# R7KA8T2AD register map
Vendor: Renesas Electronics Corporation; Series: RA8; File version: 1.10.02
CPU: CM85 r0p2, little endian, MPU, FPU, VTOR, 4 interrupt priority bits, 96 interrupts
Registers are 32-bit, read-write, reset 0x0 unless marked. A register's access mark holds for its fields unless they carry their own. Offsets are from the block's base; [hi:lo] are bit positions; {n}, {i} and the like mark numbered series; 'fields as' and 'values as' point back to an identical list.

## MFWD (part 1 of 2) — Forwarding engine
Base 0x403C0000
Same registers: MFWD_NS 0x503C0000
0x00 FWGC — General Configuration Register
  [1:0] SVM — Switch VLAN Mode
    0=No VLAN mode (VLAN not used for forwarding); 1=C-TAG mode (C-TAG used for forwarding); 2=SC-TAG mode (S-TAG used for forwarding)
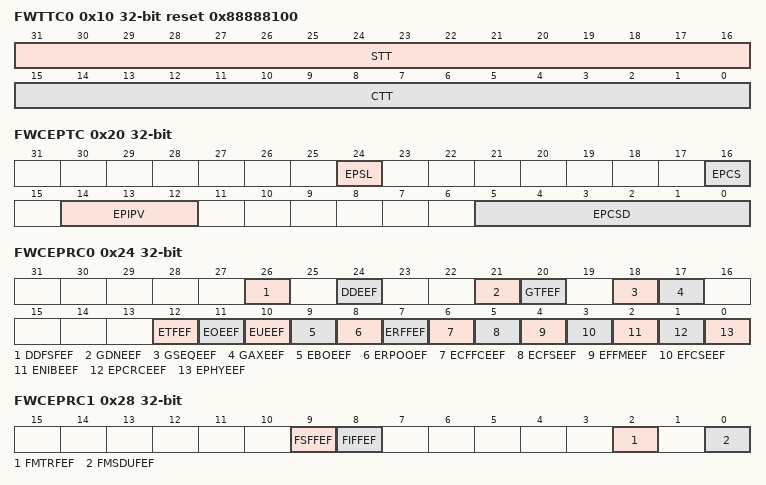
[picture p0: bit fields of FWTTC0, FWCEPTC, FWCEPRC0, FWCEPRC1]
0x10 FWTTC0 reset 0x88888100 — TAG TPID Configuration Register 0
  [31:16] STT — S-TAG TPID [801.2Q]
  [15:0] CTT — C-TAG TPID [801.2Q]
0x14 FWTTC1 reset 0xF1C1 — TAG TPID Configuration Register 1
  [15:0] RTT — R-TAG TPID [801.2CB]
0x20 FWCEPTC — CPU Exceptional Path Target Configuration Register
  [24] EPSL — Exceptional Path Security Level
  [16] EPCS — Exceptional Path CPU Select
  [14:12] EPIPV — Exceptional Path Internal Priority Value
  [5:0] EPCSD — Exceptional Path CPU Sub Destination
0x24 FWCEPRC0 — CPU Exceptional Path Reason Configuration Register 0
  [26] DDFSFEF — Direct Descriptor Format Security Filtering Exceptional Forwarding
    0=Frames with Direct Descriptor Format Security Error are discarded; 1=Frames with Direct Descriptor Format Security Error are forwarded to exceptional path
  [24] DDEEF — Direct Descriptor Error Exceptional Forwarding
    0=Frames with Direct Descriptor Error are discarded; 1=Frames with Direct Descriptor Error are forwarded to exceptional path
  [21] GDNEEF — GWCA Descriptor Number Error Exceptional Forwarding
    0=Frames received with Descriptor Number Error are discarded; 1=Frames received with Descriptor Number Error are forwarded to exceptional path
  [20] GTFEF — GWCA TAG Filtering Exceptional Forwarding
    0=Frames received with TAG Filtering flag are discarded; 1=Frames received with TAG Filtering flag are forwarded to exceptional path
  [18] GSEQEEF — GWCA Sequence Error Exceptional Forwarding
    0=Frames received with Sequence Error are discarded; 1=Frames received with Sequence Error are forwarded to exceptional path
  [17] GAXEEF — GWCA AXI Error Exceptional Forwarding
    0=Frames received with AXI Error are discarded; 1=Frames received with AXI Error are forwarded to exceptional path
  [12] ETFEF — Ethernet TAG Filtering Exceptional Forwarding
    values as GTFEF
  [11] EOEEF — Ethernet Oversize Error Exceptional Forwarding
    0=Frames received with Oversize Error are discarded; 1=Frames received with Oversize Error are forwarded to exceptional path
  [10] EUEEF — Ethernet Undersize Error Exceptional Forwarding
    0=Frames received with Undersize Error are discarded; 1=Frames received with Undersize Error are forwarded to exceptional path
  [9] EBOEEF — Ethernet Buffer Overflow Error Exceptional Forwarding
    0=Frames received with Buffer Overflow Error are discarded; 1=Frames received with Buffer Overflow Error are forwarded to exceptional path
  [8] ERPOOEF — Ethernet Reception Partially Out of Operation Exceptional Forwarding
    0=Frames received with Reception Partially Out of Operation flag are discarded; 1=Frames received with Reception Partially Out of Operation flag are forwarded to exceptional path
  [7] ERFFEF — Ethernet RMAC Frame Filtered Exceptional Forwarding
    0=Frames received with RMAC Frame Filtered flag are discarded; 1=Frames received with RMAC Frame Filtered flag are forwarded to exceptional path
  [6] ECFFCEEF — Ethernet C-Fragment FRAG_COUNT Error Exceptional Forwarding
    0=Frames received with C-Fragment FRAG_COUNT Error are discarded; 1=Frames received with C-Fragment FRAG_COUNT Error are forwarded to exceptional path
  [5] ECFSEEF — Ethernet C-Fragment SMD Error Exceptional Forwarding
    0=Frames received with C-Fragment SMD Error are discarded; 1=Frames received with C-Fragment SMD Error are forwarded to exceptional path
  [4] EFFMEEF — Ethernet Final Fragment Missing Error Exceptional Forwarding
    0=Frames received with Final Fragment Missing Error are discarded; 1=Frames received with Final Fragment Missing Error are forwarded to exceptional path
  [3] EFCSEEF — Ethernet FCS Error Exceptional Forwarding
    0=Frames received with FCS Error are discarded; 1=Frames received with FCS Error are forwarded to exceptional path
  [2] ENIBEEF — Ethernet Nibble Error Exceptional Forwarding
    0=Frames received with Nibble Error are discarded; 1=Frames received with Nibble Error are forwarded to exceptional path
  [1] EPCRCEEF — Ethernet PCH CRC Error Exceptional Forwarding
    0=Frames received with PCH CRC Error are discarded; 1=Frames received with PCH CRC Error are forwarded to exceptional path
  [0] EPHYEEF — Ethernet PHY Error Exceptional Forwarding
    0=Frames received with PHY Error are discarded; 1=Frames received with PHY Error are forwarded to exceptional path
0x28 FWCEPRC1 — CPU Exceptional Path Reason Configuration Register 1
  [9] FSFFEF — Sequence FRER Filtering Exceptional Forwarding
    0=Frames filtered by FRER Sequence recovery are discarded; 1=Frames filtered by FRER Sequence recovery are forwarded to exceptional path
  [8] FIFFEF — Individual FRER Filtering Exceptional Forwarding
    0=Frames filtered by FRER individual recovery are discarded; 1=Frames filtered by FRER individual recovery are forwarded to exceptional path
  [2] FMTRFEF — Meter Filtering Exceptional Forwarding
    0=Frames filtered by PSFP Meter filter are discarded; 1=Frames filtered by PSFP Meter filter are forwarded to exceptional path
  [0] FMSDUFEF — MSDU Filtering Exceptional Forwarding
    0=Frames filtered by PSFP MSDU filter are discarded; 1=Frames filtered by PSFP MSDU filter are forwarded to exceptional path
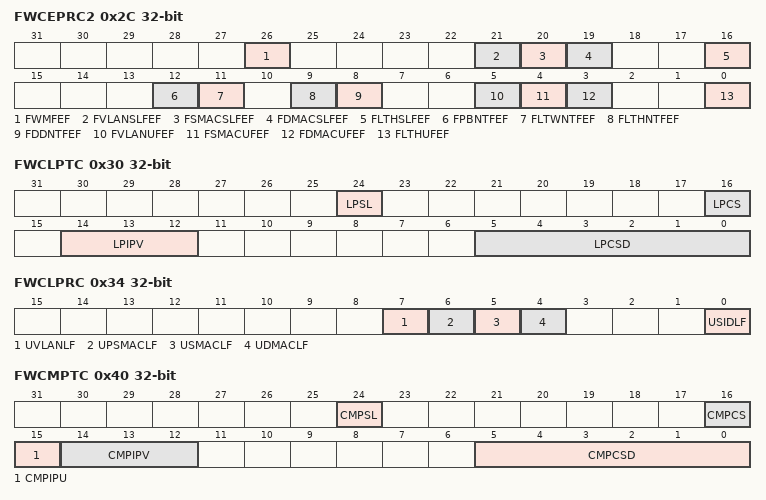
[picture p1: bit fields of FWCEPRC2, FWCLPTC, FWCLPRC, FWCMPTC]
0x2C FWCEPRC2 — CPU Exceptional Path Reason Configuration Register 2
  [26] FWMFEF — Watermark Filtering Exceptional Forwarding
    0=Frames filtered because of watermark are discarded; 1=Frames filtered because of watermark are forwarded to exceptional path
  [21] FVLANSLFEF — VLAN Source Lock Filtering Exceptional Forwarding
    0=Frames filtered because of VLAN source lock are discarded; 1=Frames filtered because of VLAN source lock are forwarded to exceptional path
  [20] FSMACSLFEF — Source MAC Source Lock Filtering Exceptional Forwarding
    0=Frames filtered because of Source MAC source lock are discarded; 1=Frames filtered because of Source MAC source lock are forwarded to exceptional path
  [19] FDMACSLFEF — Destination MAC Source Lock Filtering Exceptional Forwarding
    0=Frames filtered because of Destination MAC source lock are discarded; 1=Frames filtered because of Destination MAC source lock are forwarded to exceptional path
  [16] FLTHSLFEF — Layer 3 Source Lock Filtering Exceptional Forwarding
    0=Frames filtered because of Layer 3 source lock are discarded; 1=Frames filtered because of Layer 3 source lock are forwarded to exceptional path
  [12] FPBNTFEF — Port Based No Target Filtering Exceptional Forwarding
    0=Frames filtered because no target during Port Based forwarding is detected are discarded; 1=Frames filtered because no target during Port Based forwarding is detected are forwarded to exceptional path
  [11] FLTWNTFEF — Layer 2 No Target Filtering Exceptional Forwarding
    0=Frames filtered because the combination on VLAN destination vector and destination MAC destination vector is null are discarded; 1=Frames filtered because the combination on VLAN destination vector and destination MAC destination vector is null are forwarded to exceptional path
  [9] FLTHNTFEF — Layer 3 No Target Filtering Exceptional Forwarding
    0=Frames filtered because no target during Layer 3 forwarding is detected are discarded; 1=Frames filtered because no target during Layer 3 forwarding is detected are forwarded to exceptional path
  [8] FDDNTFEF — Direct Descriptor No Target Filtering Exceptional Forwarding
    0=Frames filtered because no target during direct forwarding is detected are discarded; 1=Frames filtered because no target during direct forwarding is detected are forwarded to exceptional path
  [5] FVLANUFEF — VLAN Unknown Filtering Exceptional Forwarding
    0=Frames filtered because their VLAN is unknown are discarded; 1=Frames filtered because their VLAN is unknown are forwarded to exceptional path
  [4] FSMACUFEF — Source MAC Unknown Filtering Exceptional Forwarding
    0=Frames filtered because their Source MAC is unknown are discarded; 1=Frames filtered because their Source MAC is unknown are forwarded to exceptional path
  [3] FDMACUFEF — Destination MAC Unknown Filtering Exceptional Forwarding
    0=Frames filtered because their Destination MAC is unknown are discarded; 1=Frames filtered because their Destination MAC is unknown are forwarded to exceptional path
  [0] FLTHUFEF — Layer 3 Unknown Filtering Exceptional Forwarding
    0=Frames filtered because their stream ID is unknown are discarded; 1=Frames filtered because their stream ID is unknown are forwarded to exceptional path
0x30 FWCLPTC — CPU Learning Path Target Configuration Register
  [24] LPSL — Learning Path Security Level
  [16] LPCS — Learning Path CPU Select
  [14:12] LPIPV — Learning Path Internal Priority Value
  [5:0] LPCSD — Learning Path CPU Sub Destination
0x34 FWCLPRC — CPU Learning Path Reason Configuration Register
  [7] UVLANLF — Unknown VLAN Learning Forwarding
    0=Frames received with an unknown VLAN are not forwarded to Learning path; 1=Frames received with an unknown VLAN are forwarded to Learning path
  [6] UPSMACLF — Unknown Port for Source MAC Learning Forwarding
    0=Frames received with an unknown port for Source MAC are not forwarded to Learning path; 1=Frames received with an unknown port for Source MAC are forwarded to Learning path
  [5] USMACLF — Unknown Source MAC Learning Forwarding
    0=Frames received with an unknown Source MAC are not forwarded to Learning path; 1=Frames received with an unknown Source MAC are forwarded to Learning path
  [4] UDMACLF — Unknown Destination MAC Learning Forwarding
    0=Frames received with an unknown destination MAC address are not forwarded to Learning path; 1=Frames received with an unknown destination MAC address are forwarded to Learning path
  [0] USIDLF — Unknown Stream ID Learning Forwarding
    0=Frames received with an unknown stream ID are not forwarded to Learning path; 1=Frames received with an unknown stream ID are forwarded to Learning path
0x40 FWCMPTC — CPU Mirroring Path Target Configuration Register
  [24] CMPSL — CPU Mirroring Path Security Level
  [16] CMPCS — CPU Mirroring Path CPU Select
  [15] CMPIPU — CPU Mirroring Path Internal Priority Update
    0=Frames mirrored to CPU path are sent with the same priority as for forwarding; 1=Frames mirrored to CPU path are sent with FWCMPTC.CMPIPV priority
  [14:12] CMPIPV — CPU Mirroring Path Internal Priority Value
  [5:0] CMPCSD — CPU Mirroring Path CPU Sub Destination
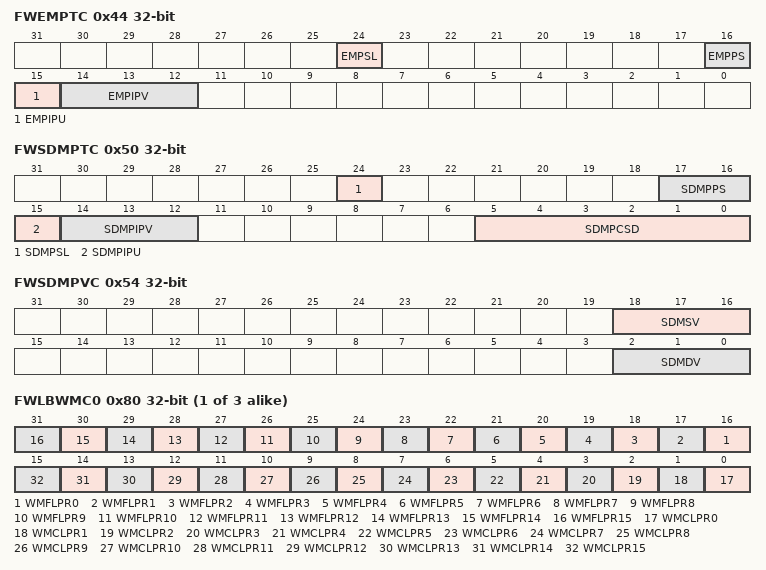
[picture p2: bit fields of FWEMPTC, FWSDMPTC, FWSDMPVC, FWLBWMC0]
0x44 FWEMPTC — Ethernet Mirroring Path Target Configuration Register
  [24] EMPSL — Ethernet Mirroring Path Security Level
  [16] EMPPS — Ethernet Mirroring Path Port Select
  [15] EMPIPU — Ethernet Mirroring Path Internal Priority Update
    0=Frames mirrored to Ethernet path are sent with the same priority as for forwarding; 1=Frames mirrored to Ethernet path are sent with FWEMPTC.EMPIPV priority
  [14:12] EMPIPV — Ethernet Mirroring Path Internal Priority Value
0x50 FWSDMPTC — Source-Destination Mirroring Path Target Configuration Register
  [24] SDMPSL — Source-Destination Mirroring Path Security Level
  [17:16] SDMPPS — Source-Destination Mirroring Path Port Select
  [15] SDMPIPU — Source-Destination Mirroring Path Internal Priority Update
    0=Frames mirrored to Source-Destination path are sent with the same priority as for forwarding; 1=Frames mirrored to Source-Destination path are sent with FWSDMPTC.SDMPIPV priority
  [14:12] SDMPIPV — Source-Destination Mirroring Path Internal Priority Value
  [5:0] SDMPCSD — Source-Destination Mirroring Path CPU Sub Destination
0x54 FWSDMPVC — Source-Destination Mirroring Path Vector Configuration Register
  [18:16] SDMSV — Source-Destination Mirroring Source Vector
  [2:0] SDMDV — Source-Destination Mirroring Destination Vector
{0x80+4i} FWLBWMC{i} (i=0..2) — Port {i} Level Based Watermark Configuration Register
  [n+16] WMFLPR{n} (n=0..15) — Watermark Flush Level Priority n Reject (n = 0 to 15)
    0=Frames coming for port i and that should be forwarded with {DEI,IPV} equal to j are forwarded; 1=Frames coming for port i and that should be forwarded with {DEI,IPV} equal to j are discarded when watermark flush level is set for port i (WM.FLUSH[i] is set [COMA])
  [n] WMCLPR{n} (n=0..15) — Watermark Critical Level Priority n Reject (n = 0 to 15)
    0=Frames coming for port i and that should be forwarded with {DEI,IPV} equal to j are forwarded; 1=Frames coming for port i and that should be forwarded with {DEI,IPV} equal to j are discarded when watermark critical level is set for port i (WM.CRITICAL[i] is set [COMA])
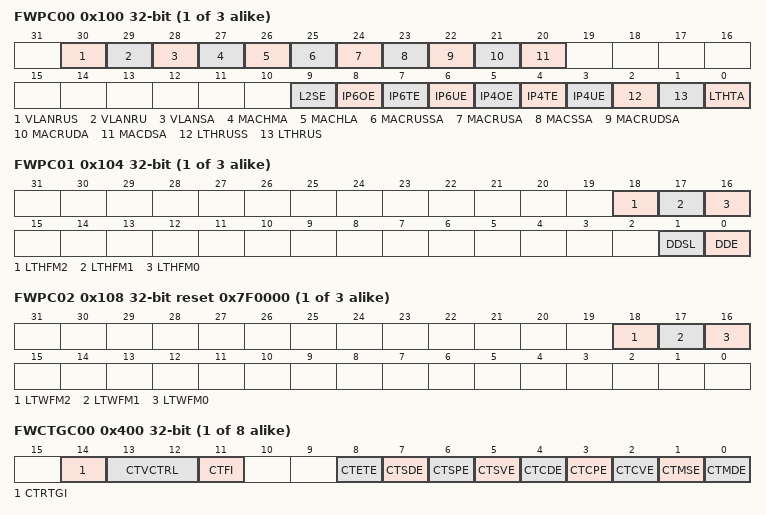
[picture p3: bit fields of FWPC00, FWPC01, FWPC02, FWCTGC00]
{0x100+0x10*i} FWPC{i}0 (i=0..2) — Port {i} Configuration Register 0
  [30] VLANRUS — VLAN Reject Unknown Secure
    0=Unknown secure VLAN coming from source port i are not rejected; 1=Unknown secure VLAN coming from source port i are rejected
  [29] VLANRU — VLAN Reject Unknown
    0=Unknown VLAN coming from source port i are not rejected; 1=Unknown VLAN coming from source port i are rejected
  [28] VLANSA — VLAN Search Active
    0=VLAN search is disabled for source port i; 1=VLAN search is enabled for source port i
  [27] MACHMA — MAC Hardware Migration Active
    0=Known unicast MAC Source addresses coming from source port i with a wrong source port in MAC.DV are not overwritten; 1=Known unicast MAC Source addresses coming from source port i with a wrong source port in MAC.DV are overwritten
  [26] MACHLA — MAC Hardware Learning Active
    0=Unknown unicast MAC Source addresses coming from source port i are not added to the MAC table; 1=Unknown unicast MAC Source addresses coming from source port i are added to the MAC table
  [25] MACRUSSA — MAC Reject Unknown Source Secure Addresses
    0=Unknown secure MAC Source addresses coming from source port i are not rejected; 1=Unknown secure MAC Source addresses coming from source port i are rejected
  [24] MACRUSA — MAC Reject Unknown Source Addresses
    0=Unknown MAC Source addresses coming from source port i are not rejected; 1=Unknown MAC Source addresses coming from source port i are rejected
  [23] MACSSA — MAC Source Search Active
    0=MAC Source search is disabled for source port i; 1=MAC Source search is enabled for source port i
  [22] MACRUDSA — MAC Reject Unknown Destination Secure Addresses
    0=Unknown secure MAC Destination addresses coming from source port i are not rejected; 1=Unknown secure MAC Destination addresses coming from source port i are rejected
  [21] MACRUDA — MAC Reject Unknown Destination Addresses
    0=Unknown MAC Destination addresses coming from source port i are not rejected; 1=Unknown MAC Destination addresses coming from source port i are rejected
  [20] MACDSA — MAC Destination Search Active
    0=MAC Destination search is disabled for source port i; 1=MAC Destination search is enabled for source port i
  [9] L2SE — L2 Stream Enable
    0=L2 stream disabled for source port i; 1=L2 stream enabled for source port i
  [8] IP6OE — IPv6 Other Enable
    0=Non-TCP non-UDP IPv6 detection disabled for source port i; 1=Non-TCP non-UDP IPv6 detection enabled for source port i
  [7] IP6TE — IPv6 TCP Enable
    0=IPv6/TCP detection disabled for source port i; 1=IPv6/TCP detection enabled for source port i
  [6] IP6UE — IPv6 UDP Enable
    0=IPv6/UDP detection disabled for source port i; 1=IPv6/UDP detection enabled for source port i
  [5] IP4OE — IPv4 Other Enable
    0=Non-TCP non-UDP IPv4 detection disabled for source port i; 1=Non-TCP non-UDP IPv4 detection enabled for source port i
  [4] IP4TE — IPv4 TCP Enable
    0=IPv4/TCP detection disabled for source port i; 1=IPv4/TCP detection enabled for source port i
  [3] IP4UE — IPv4 UDP Enable
    0=IPv4/UDP detection disabled for source port i; 1=IPv4/UDP detection enabled for source port i
  [2] LTHRUSS — L3 Reject Unknown Secure Streams
    0=Unknown secure streams coming from source port i are not rejected; 1=Unknown secure streams coming from source port i are rejected
  [1] LTHRUS — L3 Reject Unknown Streams
    0=Unknown streams coming from source port i are not rejected; 1=Unknown streams coming from source port i are rejected
  [0] LTHTA — L3 Table Active
    0=L3 table is disabled for source port i; 1=L3 table is enabled for source port i
{0x104+0x10*i} FWPC{i}1 (i=0..2) — Port {i} Configuration Register 1
  [18] LTHFM2 — Layer 3 Forwarding Mask n (n = 0 to 2)
    0=Frames forwarded by Layer 3 forwarding can be forwarded to port j; 1=Frames forwarded by Layer 3 forwarding cannot be forwarded to port j
  [17] LTHFM1 — Layer 3 Forwarding Mask n (n = 0 to 2)
    values as LTHFM2
  [16] LTHFM0 — Layer 3 Forwarding Mask n (n = 0 to 2)
    values as LTHFM2
  [1] DDSL — Direct Descriptor Security Level
    0=Secured Direct Descriptor discarded for port i; 1=Secured Direct Descriptor forwarded for port i
  [0] DDE — Direct Descriptor Enable
    0=Direct Descriptor disabled for port i; 1=Direct Descriptor enabled for port i
{0x108+0x10*i} FWPC{i}2 (i=0..2) reset 0x7F0000 — Port {i} Configuration Register 2
  [all] fields
    0=Frames forwarded by Layer 2 forwarding can be forwarded to port j; 1=Frames forwarded by Layer 2 forwarding cannot be forwarded to port j
  [18] LTWFM2 — Layer 2 Forwarding Mask n (n = 0 to 2)
  [17] LTWFM1 — Layer 2 Forwarding Mask n (n = 0 to 2)
  [16] LTWFM0 — Layer 2 Forwarding Mask n (n = 0 to 2)
{0x400+0x40*i} FWCTGC{i}0 (i=0..7) — Cut-Through General Configuration Register i0
  [14] CTRTGI — Cut-Through R-TAG In [GWCA] [ETHA]
    0=R-TAG is not included in cut-through frame; 1=R-TAG is included in cut-through frame
  [13:12] CTVCTRL — Cut-Through VLAN Control [GWCA] [ETHA]
    0=The ingress matching separation rule i frame is a No TAG frame; 1=The ingress matching separation rule i frame is a C-TAG frame; 2=The ingress matching separation rule i frame is an SC-TAG frame; 3=The ingress matching separation rule i frame is a CoS TAG frame
  [11] CTFI — Cut-Through FCS In
    0=The frame matching separation rule i as no FCS included; 1=The frame matching separation rule i as an FCS included
  [8] CTETE — Cut-Through Ethernet Type Enable
    0=Ethernet Type not included in Cut-Through separation for separation rule i; 1=Ethernet Type included in Cut-Through separation for separation rule i
  [7] CTSDE — Cut-Through S-TAG DEI Enable
    0=S-TAG DEI not included in Cut-Through separation for separation rule i; 1=S-TAG DEI included in Cut-Through separation for separation rule i
  [6] CTSPE — Cut-Through S-TAG PCP Enable
    0=S-TAG PCP not included in Cut-Through separation for separation rule i; 1=S-TAG PCP included in Cut-Through separation for separation rule i
  [5] CTSVE — Cut-Through S-TAG VLAN Enable
    0=S-TAG VLAN not included in Cut-Through separation for separation rule i; 1=S-TAG VLAN included in Cut-Through separation for separation rule i
  [4] CTCDE — Cut-Through C-TAG DEI Enable
    0=C-TAG DEI not included in Cut-Through separation for separation rule i; 1=C-TAG DEI included in Cut-Through separation for separation rule i
  [3] CTCPE — Cut-Through C-TAG PCP Enable
    0=C-TAG PCP not included in Cut-Through separation for separation rule i; 1=C-TAG PCP included in Cut-Through separation for separation rule i
  [2] CTCVE — Cut-Through C-TAG VLAN Enable
    0=C-TAG VLAN not included in Cut-Through separation for separation rule i; 1=C-TAG VLAN included in Cut-Through separation for separation rule i
  [1] CTMSE — Cut-Through MAC Source Enable
    0=MAC Source not included in Cut-Through separation for separation rule i; 1=MAC Source included in Cut-Through separation for separation rule i
  [0] CTMDE — Cut-Through MAC Destination Enable
    0=MAC destination not included in Cut-Through separation for separation rule i; 1=MAC destination included in Cut-Through separation for separation rule i
{0x404+0x40*i} FWCTGC{i}1 (i=0..7) — Cut-Through General Configuration Register i1
  [25:0] CTMT — Cut-Through Maximum time
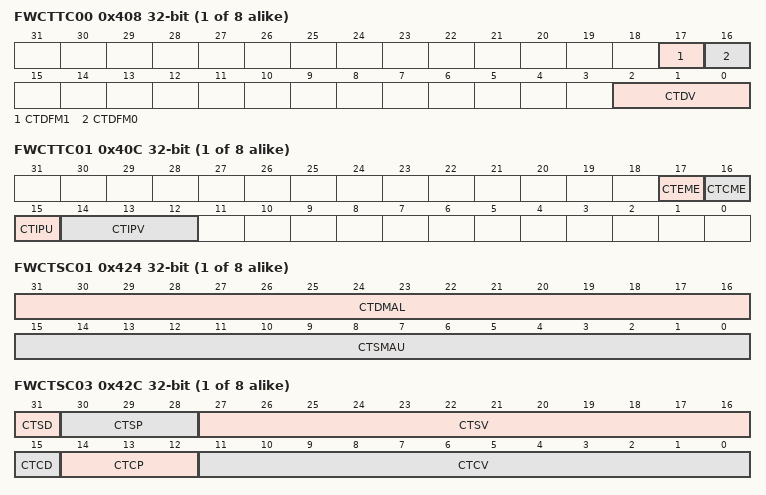
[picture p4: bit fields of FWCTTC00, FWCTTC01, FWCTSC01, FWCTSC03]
{0x408+0x40*i} FWCTTC{i}0 (i=0..7) — Cut-Through Target Configuration Register i0
  [17] CTDFM1 — Cut-Through Destination n Forwarding Mode (n = 0 to 1)
    0=Frame is forwarded in Cut-through mode; 1=Frame is forwarded in Store and forward mode
  [16] CTDFM0 — Cut-Through Destination n Forwarding Mode (n = 0 to 1)
    values as CTDFM1
  [2:0] CTDV — Cut-through Destination Vector
{0x40C+0x40*i} FWCTTC{i}1 (i=0..7) — Cut-Through Target Configuration Register i1
  [17] CTEME — Cut-through Ethernet Mirroring Enable
    0=Ethernet mirroring is disabled for frames matching separation rule i; 1=Ethernet mirroring is enabled for frames matching separation rule i
  [16] CTCME — Cut-through CPU Mirroring Enable
    0=CPU mirroring is disabled for frames matching separation rule i; 1=CPU mirroring is enabled for frames matching separation rule i
  [15] CTIPU — Cut-through Internal Priority Update
    0=Use the output descriptor priority to forwarding frames matching separation rule i; 1=Use FWCTTCi1.CTIPV priority to forwarding frames matching separation rule i
  [14:12] CTIPV — Cut-through Internal Priority Value
{0x410+0x40*i} FWCTTC{i}20 (i=0..7) — Cut-Through Target Configuration Register i20
  [5:0] CTCSD — Cut-Through CPU Sub Destination
{0x420+0x40*i} FWCTSC{i}0 (i=0..7) — Cut-Through Separation Configuration Register i0
  [31:0] CTDMAU — Cut-Through Destination MAC Address Upper Part
{0x424+0x40*i} FWCTSC{i}1 (i=0..7) — Cut-Through Separation Configuration Register i1
  [31:16] CTDMAL — Cut-Through Destination MAC Address Lower Part
  [15:0] CTSMAU — Cut-Through Source MAC Address Upper Part
{0x428+0x40*i} FWCTSC{i}2 (i=0..7) — Cut-Through Separation Configuration Register i2
  [31:0] CTSMAL — Cut-Through Source MAC Address Lower Part
{0x42C+0x40*i} FWCTSC{i}3 (i=0..7) — Cut-Through Separation Configuration Register i3
  [31] CTSD — Cut-Through S-TAG DEI
  [30:28] CTSP — Cut-Through S-TAG PCP
  [27:16] CTSV — Cut-Through S-TAG VLAN
  [15] CTCD — Cut-Through C-TAG DEI
  [14:12] CTCP — Cut-Through C-TAG PCP
  [11:0] CTCV — Cut-Through C-TAG VLAN
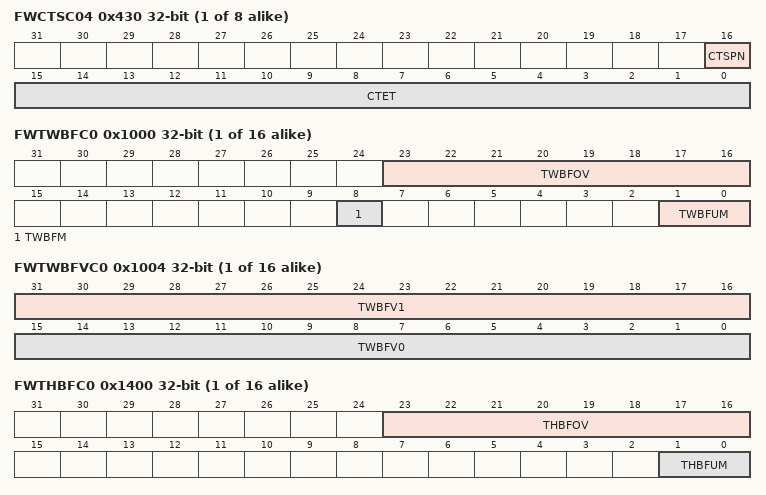
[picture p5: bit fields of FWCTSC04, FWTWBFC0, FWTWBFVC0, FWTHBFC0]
{0x430+0x40*i} FWCTSC{i}4 (i=0..7) — Cut-Through Separation Configuration Register i4
  [16] CTSPN — Cut-Through Source Port Number
  [15:0] CTET — Cut-Through Ethernet Type
{0x1000+0x10*i} FWTWBFC{i} (i=0..15) — Two-Byte Filter Configuration Register {i}
  [23:16] TWBFOV — Two-Byte Filter Offset Value
  [8] TWBFM — Two-Byte Filtering Mode
    0=Offset filtering; 1=VLAN TAG filtering
  [1:0] TWBFUM — Two-Byte Filter Unit Mode
    0=Mask mode; 1=Expand mode; 2=Precise mode
{0x1004+0x10*i} FWTWBFVC{i} (i=0..15) — Two-Byte Filter Value Configuration Register {i}
  [31:16] TWBFV1 — Two-Byte Filter Value 1
  [15:0] TWBFV0 — Two-Byte Filter Value 0
{0x1400+0x10*i} FWTHBFC{i} (i=0..15) — Three-Byte Filter Configuration Register {i}
  [23:16] THBFOV — Three-Byte Filter Offset Value
  [1:0] THBFUM — Three-Byte Filter Unit Mode
    0=Mask mode; 1=Expand mode; 2=Precise mode
{0x1404+0x10*i} FWTHBFV0C{i} (i=0..15) — Three-Byte Filter Value 0 Configuration Register {i}
  [23:0] THBFV0 — Three-Byte Filter Value 0
{0x1408+0x10*i} FWTHBFV1C{i} (i=0..15) — Three-Byte Filter Value 1 Configuration Register {i}
  [23:0] THBFV1 — Three-Byte Filter Value 1
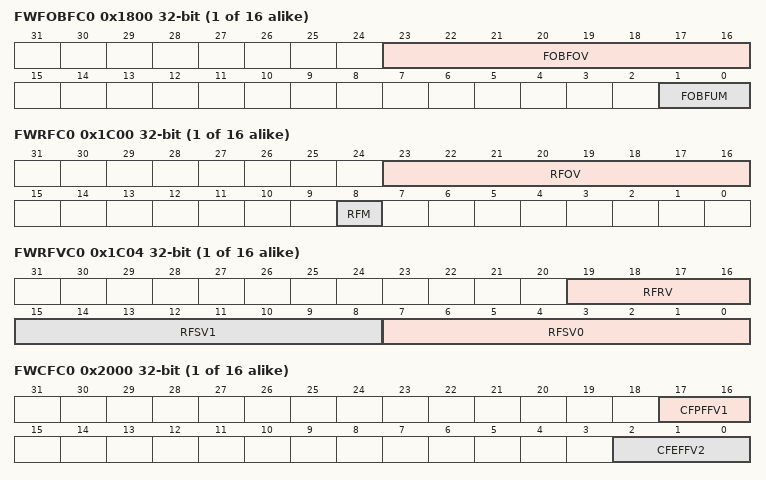
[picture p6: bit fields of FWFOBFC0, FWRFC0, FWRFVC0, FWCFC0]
{0x1800+0x10*i} FWFOBFC{i} (i=0..15) — Four-Byte Filter Configuration Register {i}
  [23:16] FOBFOV — Four-Byte Filter Offset Value
  [1:0] FOBFUM — Four-Byte Filter Unit Mode
    0=Mask mode; 1=Expand mode; 2=Precise mode
{0x1804+0x10*i} FWFOBFV0C{i} (i=0..15) — Four-Byte Filter Value 0 Configuration Register {i}
  [31:0] FOBFV0 — Four-Byte Filter Value 0
{0x1808+0x10*i} FWFOBFV1C{i} (i=0..15) — Four-Byte Filter Value 1 Configuration Register {i}
  [31:0] FOBFV1 — Four-Byte Filter Value 1
{0x1C00+0x10*i} FWRFC{i} (i=0..15) — Range Filter Configuration Register {i}
  [23:16] RFOV — Range Filter Offset Value
  [8] RFM — Range Filtering Mode
    0=Offset filtering; 1=VLAN TAG filtering
{0x1C04+0x10*i} FWRFVC{i} (i=0..15) — Range Filter Value Configuration Register {i}
  [19:16] RFRV — Range Filter Range Value
  [15:8] RFSV1 — Range Filter Start Value 1
  [7:0] RFSV0 — Range Filter Start Value 0
{0x2000+0x40*i} FWCFC{i} (i=0..15) — Cascade Filter Configuration Register {i}
  [17:16] CFPFFV1 to CFPFFV0 — Cascade Filter E-Frame Filter Valid n (n = 0 to 1)
  [2:0] CFEFFV2 to CFEFFV0 — Cascade Filter E-Frame Filter Valid n (n = 0 to 2)
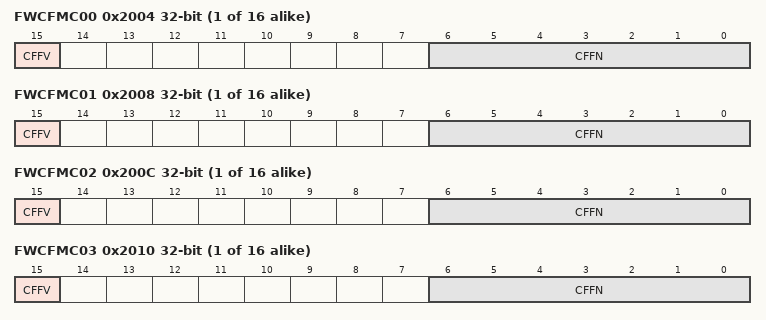
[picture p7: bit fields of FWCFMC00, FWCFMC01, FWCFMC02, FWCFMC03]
{0x2004+0x40*i} FWCFMC{i}0 (i=0..15) — Cascade Filter Mapping Configuration Register i0
  [15] CFFV — Cascade Filter Valid
  [6:0] CFFN — Cascade Filter Filter Number
{0x2008+0x40*i} FWCFMC{i}1 (i=0..15) — Cascade Filter Mapping Configuration Register i1
  fields as FWCFMC00
{0x200C+0x40*i} FWCFMC{i}2 (i=0..15) — Cascade Filter Mapping Configuration Register i2
  fields as FWCFMC00
{0x2010+0x40*i} FWCFMC{i}3 (i=0..15) — Cascade Filter Mapping Configuration Register i3
  fields as FWCFMC00
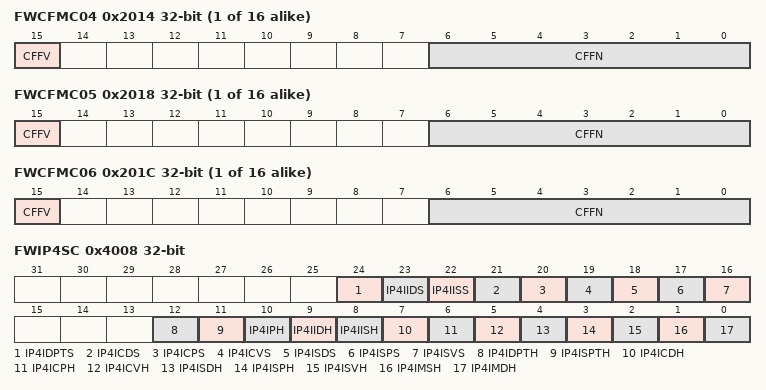
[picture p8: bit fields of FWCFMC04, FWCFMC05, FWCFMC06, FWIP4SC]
{0x2014+0x40*i} FWCFMC{i}4 (i=0..15) — Cascade Filter Mapping Configuration Register i4
  fields as FWCFMC00
{0x2018+0x40*i} FWCFMC{i}5 (i=0..15) — Cascade Filter Mapping Configuration Register i5
  fields as FWCFMC00
{0x201C+0x40*i} FWCFMC{i}6 (i=0..15) — Cascade Filter Mapping Configuration Register i6
  fields as FWCFMC00
0x4008 FWIP4SC — IPv4 Stream Configuration Register
  [24] IP4IDPTS — IPv4 Include Destination Port in Stream
    0=TCP/UDP Destination port is not included in L3 IPv4 stream ID; 1=TCP/UDP Destination port is included in L3 IPv4 stream ID
  [23] IP4IIDS — IPv4 Include IP Destination in Stream
    0=IPv4 Destination IP address is not included in L3 IPv4 stream ID; 1=IPv4 Destination IP address is included in L3 IPv4 stream ID
  [22] IP4IISS — IPv4 Include IP Source in Stream
    0=IPv4 Source IP address is not included in L3 IPv4 stream ID; 1=IPv4 Source IP address is included in L3 IPv4 stream ID
  [21] IP4ICDS — IPv4 Include C-TAG DEI in Stream
    0=C-TAG DEI is not included in L3 IPv4 stream ID; 1=C-TAG DEI is included in L3 IPv4 stream ID
  [20] IP4ICPS — IPv4 Include C-TAG PCP in Stream
    0=C-TAG PCP is not included in L3 IPv4 stream ID; 1=C-TAG PCP is included in L3 IPv4 stream ID
  [19] IP4ICVS — IPv4 Include C-TAG VLAN ID in Stream
    0=C-TAG VLAN ID is not included in L3 IPv4 stream ID; 1=C-TAG VLAN ID is included in L3 IPv4 stream ID
  [18] IP4ISDS — IPv4 Include S-TAG DEI in Stream
    0=S-TAG DEI is not included in L3 IPv4 stream ID; 1=S-TAG DEI is included in L3 IPv4 stream ID
  [17] IP4ISPS — IPv4 Include S-TAG PCP in Stream
    0=S-TAG PCP is not included in L3 IPv4 stream ID; 1=S-TAG PCP is included in L3 IPv4 stream ID
  [16] IP4ISVS — IPv4 Include S-TAG VLAN ID in Stream
    0=S-TAG VLAN ID is not included in L3 IPv4 stream ID; 1=S-TAG VLAN ID is included in L3 IPv4 stream ID
  [12] IP4IDPTH — IPv4 Include Destination Port in Hash
    0=TCP/UDP Destination port is not included in hash calculation; 1=TCP/UDP Destination port is included in hash calculation
  [11] IP4ISPTH — IPv4 Include Source Port in Hash
    0=TCP/UDP Source port is not included in hash calculation; 1=TCP/UDP Source port is included in hash calculation
  [10] IP4IPH — IPv4 Include Protocol in Hash
    0=IPv4 Protocol is not included in hash calculation; 1=IPv4 Protocol is included in hash calculation
  [9] IP4IIDH — IPv4 Include IP Destination in Hash
    0=IPv4 Destination IP address is not included in hash calculation; 1=IP v4 Destination IP address is included in hash calculation
  [8] IP4IISH — IPv4 Include IP Source in Hash
    0=IPv4 Source IP address is not included in hash calculation; 1=IPv4 Source IP address is included in hash calculation
  [7] IP4ICDH — IPv4 Include C-TAG DEI in Hash
    0=C-TAG DEI is not included in hash calculation; 1=C-TAG DEI is included in hash calculation
  [6] IP4ICPH — IPv4 Include C-TAG PCP in Hash
    0=C-TAG PCP is not included in hash calculation; 1=C-TAG PCP is included in hash calculation
  [5] IP4ICVH — IPv4 Include C-TAG VLAN ID in Hash
    0=C-TAG VLAN ID is not included in hash calculation; 1=C-TAG VLAN ID is included in hash calculation
  [4] IP4ISDH — IPv4 Include S-TAG DEI in Hash
    0=S-TAG DEI is not included in hash calculation; 1=S-TAG DEI is included in hash calculation
  [3] IP4ISPH — IPv4 Include S-TAG PCP in Hash
    0=S-TAG PCP is not included in hash calculation; 1=S-TAG PCP is included in hash calculation
  [2] IP4ISVH — IPv4 Include S-TAG VLAN ID in Hash
    0=S-TAG VLAN ID is not included in hash calculation; 1=S-TAG VLAN ID is included in hash calculation
  [1] IP4IMSH — IPv4 Include MAC Source in Hash
    0=MAC Source address is not included in hash calculation; 1=MAC Source address is included in hash calculation
  [0] IP4IMDH — IPv4 Include MAC Destination in Hash
    0=MAC Destination address is not included in hash calculation; 1=MAC Destination address is included in hash calculation
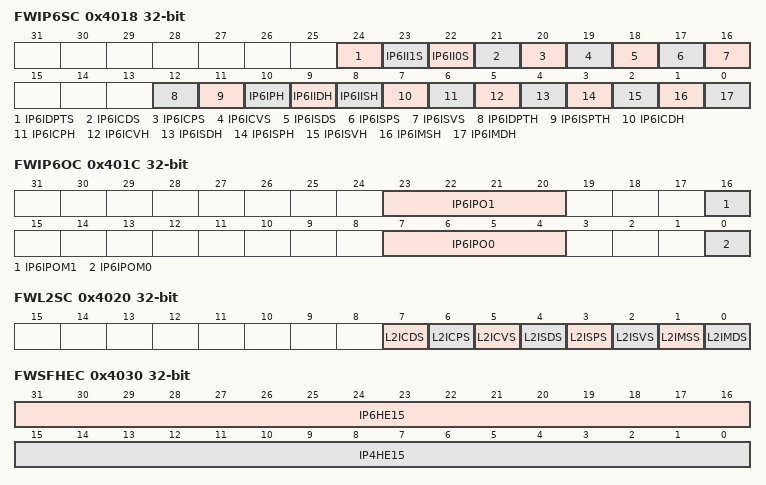
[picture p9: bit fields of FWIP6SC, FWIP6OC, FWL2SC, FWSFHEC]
0x4018 FWIP6SC — IPv6 Stream Configuration Register
  [24] IP6IDPTS — IPv6 Include Destination Port in Stream
    0=TCP/UDP Destination port is not included in L3 IPv6 stream ID; 1=TCP/UDP Destination port is included in L3 IPv6 stream ID
  [23] IP6II1S — IPv6 Include IP 1 in Stream
    0=IPv6 IP address part 1 is not included in L3 IPv6 stream ID; 1=IPv6 IP address part 1 is included in L3 IPv6 stream ID
  [22] IP6II0S — IPv6 Include IP 0 in Stream
    0=IPv6 IP address part 0 is not included in L3 IPv6 stream ID; 1=IPv6 IP address part 0 is included in L3 IPv6 stream ID
  [21] IP6ICDS — IPv6 Include C-TAG DEI in Stream
    0=C-TAG DEI is not included in L3 IPv6 stream ID; 1=C-TAG DEI is included in L3 IPv6 stream ID
  [20] IP6ICPS — IPv6 Include C-TAG PCP in Stream
    0=C-TAG PCP is not included in L3 IPv6 stream ID; 1=C-TAG PCP is included in L3 IPv6 stream ID
  [19] IP6ICVS — IPv6 Include C-TAG VLAN ID in Stream
    0=C-TAG VLAN ID is not included in L3 IPv6 stream ID; 1=C-TAG VLAN ID is included in L3 IPv6 stream ID
  [18] IP6ISDS — IPv6 Include S-TAG DEI in Stream
    0=S-TAG DEI is not included in L3 IPv6 stream ID; 1=S-TAG DEI is included in L3 IPv6 stream ID
  [17] IP6ISPS — IPv6 Include S-TAG PCP in Stream
    0=S-TAG PCP is not included in L3 IPv6 stream ID; 1=S-TAG PCP is included in L3 IPv6 stream ID
  [16] IP6ISVS — IPv6 Include S-TAG VLAN ID in Stream
    0=S-TAG VLAN ID is not included in L3 IPv6 stream ID; 1=S-TAG VLAN ID is included in L3 IPv6 stream ID
  [12] IP6IDPTH — IPv6 Include Destination Port in Hash
    values as FWIP4SC.IP4IDPTH
  [11] IP6ISPTH — IPv6 Include Source Port in Hash
    values as FWIP4SC.IP4ISPTH
  [10] IP6IPH — IPv6 Include Protocol in Hash (Next Header)
    0=IPv6 Protocol is not included in hash calculation; 1=IPv6 Protocol is included in hash calculation
  [9] IP6IIDH — IPv6 Include IP Destination in Hash
    0=IPv6 Destination IP address is not included in hash calculation; 1=IPv6 Destination IP address is included in hash calculation
  [8] IP6IISH — IPv6 Include IP Source in Hash
    0=IPv6 Source IP address is not included in hash calculation; 1=IPv6 Source IP address is included in hash calculation
  [7] IP6ICDH — IPv6 Include C-TAG DEI in Hash
    values as FWIP4SC.IP4ICDH
  [6] IP6ICPH — IPv6 Include C-TAG PCP in Hash
    values as FWIP4SC.IP4ICPH
  [5] IP6ICVH — IPv6 Include C-TAG VLAN ID in Hash
    values as FWIP4SC.IP4ICVH
  [4] IP6ISDH — IPv6 Include S-TAG DEI in Hash
    values as FWIP4SC.IP4ISDH
  [3] IP6ISPH — IPv6 Include S-TAG PCP in Hash
    values as FWIP4SC.IP4ISPH
  [2] IP6ISVH — IPv6 Include S-TAG VLAN ID in Hash
    values as FWIP4SC.IP4ISVH
  [1] IP6IMSH — IPv6 Include MAC Source in Hash
    values as FWIP4SC.IP4IMSH
  [0] IP6IMDH — IPv6 Include MAC Destination in Hash
    values as FWIP4SC.IP4IMDH
0x401C FWIP6OC — IPv6 Offset Configuration Register
  [23:20] IP6IPO1 — IPv6 IP Offset 1
  [16] IP6IPOM1 — IPv6 IP Offset mode 1
    0=IPv6 IP address part 1 is extracted from IP source address; 1=IPv6 IP address part 1 is extracted from IP destination address
  [7:4] IP6IPO0 — IPv6 IP Offset 0
  [0] IP6IPOM0 — IPv6 IP Offset mode 0
    0=IPv6 IP address part 0 is extracted from IP source address; 1=IPv6 IP address part 0 is extracted from IP destination address
0x4020 FWL2SC — Layer 2 Stream Configuration Register
  [7] L2ICDS — Layer 2 Include C-TAG DEI in Stream
    0=MAC C-TAG DEI is not included in L2 stream ID; 1=MAC C-TAG DEI is included in L2 stream ID
  [6] L2ICPS — Layer 2 Include C-TAG PCP ID in Stream
    0=MAC C-TAG PCP is not included in L2 stream ID; 1=MAC C-TAG PCP is included in L2 stream ID
  [5] L2ICVS — Layer 2 Include C-TAG VLAN ID in Stream
    0=MAC C-TAG VLAN ID is not included in L2 stream ID; 1=MAC C-TAG VLAN ID is included in L2 stream ID
  [4] L2ISDS — Layer 2 Include S-TAG DEI in Stream
    0=MAC S-TAG DEI is not included in L2 stream ID; 1=MAC S-TAG DEI is included in L2 stream ID
  [3] L2ISPS — Layer 2 Include S-TAG PCP ID in Stream
    0=MAC S-TAG PCP is not included in L2 stream ID; 1=MAC S-TAG PCP is included in L2 stream ID
  [2] L2ISVS — Layer 2 Include S-TAG VLAN ID in Stream
    0=MAC S-TAG VLAN ID is not included in L2 stream ID; 1=MAC S-TAG VLAN ID is included in L2 stream ID
  [1] L2IMSS — Layer 2 Include MAC Source in Stream
    0=MAC Source address is not included in L2 stream ID; 1=MAC Source address is included in L2 stream ID
  [0] L2IMDS — Layer 2 Include MAC Destination in Stream
    0=MAC Destination address is not included in L2 stream ID; 1=MAC Destination address is included in L2 stream ID
0x4030 FWSFHEC — Stream Filter Hash Equation Configuration Register
  [31:16] IP6HE15 to IP6HE0 — IPv6 Stream Filter Hash Equation n (n = 0 to 15)
  [15:0] IP4HE15 to IP4HE0 — IPv4 Stream Filter Hash Equation n (n = 0 to 15)
0x4040 FWSHCR0 — Software Hash Calculation Request Register 0
  [31:0] SHCMDP0 — Software Hash Calculation MAC Destination Part 0
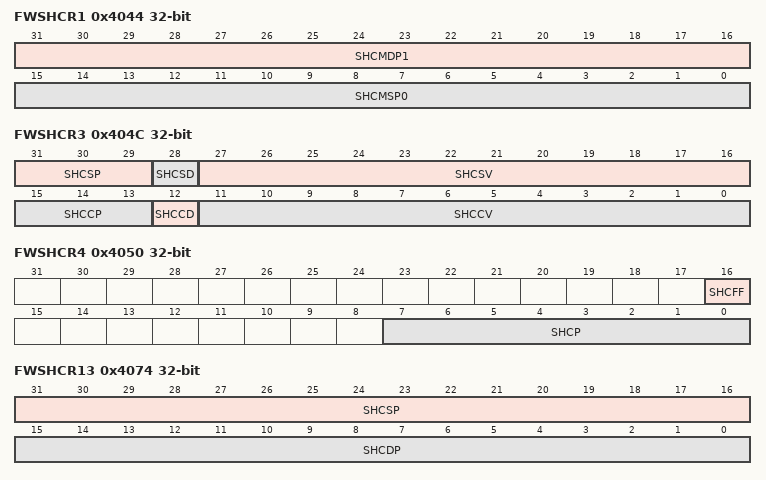
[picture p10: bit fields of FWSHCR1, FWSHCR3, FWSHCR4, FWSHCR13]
0x4044 FWSHCR1 — Software Hash Calculation Request Register 1
  [31:16] SHCMDP1 — Software Hash Calculation MAC Destination Part 1
  [15:0] SHCMSP0 — Software Hash Calculation MAC Source Part 0
0x4048 FWSHCR2 — Software Hash Calculation Request Register 2
  [31:0] SHCMSP1 — Software Hash Calculation MAC Source Part 1
0x404C FWSHCR3 — Software Hash Calculation Request Register 3
  [31:29] SHCSP — Software Hash Calculation S-TAG PCP
  [28] SHCSD — Software Hash Calculation S-TAG DEI
  [27:16] SHCSV — Software Hash Calculation S-TAG VLANs
  [15:13] SHCCP — Software Hash Calculation C-TAG PCP
  [12] SHCCD — Software Hash Calculation C-TAG DEI
  [11:0] SHCCV — Software Hash Calculation C-TAG VLAN
0x4050 FWSHCR4 — Software Hash Calculation Request Register 4
  [16] SHCFF — Software Hash Calculation Frame Format
    0=IPv4 Hash Calculation; 1=IPv6 Hash Calculation
  [7:0] SHCP — Software Hash Calculation Protocol (NextHeader for IPv6)
{0x4040+4i} FWSHCR{i} (i=5..8) — Software Hash Calculation Request Register {i}
  [31:0] SHCISP{i-5} — Software Hash Calculation IP Source Part {i-5}
0x4064 FWSHCR9 — Software Hash Calculation Request Register 9
  [31:0] SHCIDP0 — Software Hash Calculation IP Destination Part 0
0x4068 FWSHCR10 — Software Hash Calculation Request Register 10
  [31:0] SHCIDP1 — Software Hash Calculation IP Source Destination Part 1
0x406C FWSHCR11 — Software Hash Calculation Request Register 11
  [31:0] SHCIDP2 — Software Hash Calculation IP Destination Part 2
0x4070 FWSHCR12 — Software Hash Calculation Request Register 12
  [31:0] SHCIDP3 — Software Hash Calculation IP Destination Part 3
0x4074 FWSHCR13 — Software Hash Calculation Request Register 13
  [31:16] SHCSP — Software Hash Calculation Source Port
  [15:0] SHCDP — Software Hash Calculation Destination Port
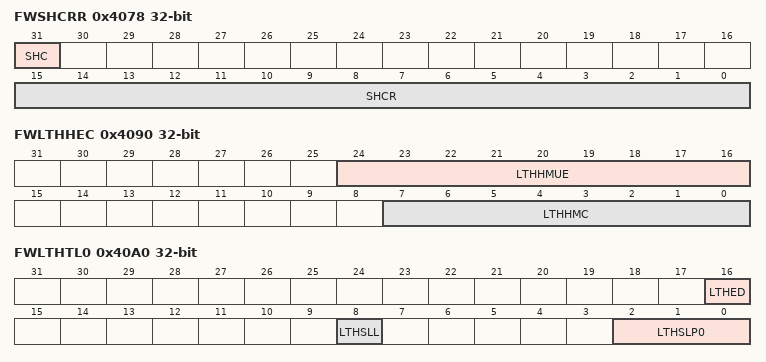
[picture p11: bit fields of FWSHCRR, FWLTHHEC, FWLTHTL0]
0x4078 FWSHCRR ro — Software Hash Calculation Request Result Register
  [31] SHC — Software Hash Calculation
  [15:0] SHCR — Software Hash Calculation Result
0x4090 FWLTHHEC — L3 Hash Entry Configuration Register
  [24:16] LTHHMUE — L3 Hash Maximum Unsecure Entry
  [7:0] LTHHMC — L3 Hash Maximum Collision
0x4094 FWLTHHC — L3 Hash Configuration Register
  [7:0] LTHHE7 to LTHHE0 — L3 Hash Equation n (n = 0 to 7)
0x40A0 FWLTHTL0 — L3 Table Learn Register 0
  [16] LTHED — L3 Entry Delete
    0=Learn/overwrite the set stream ID in L3 table; 1=Delete the set stream ID in L3 table
  [8] LTHSLL — L3 Security Level Learn
  [2:0] LTHSLP0 — L3 Stream Learn Part 0
